VERSION ""

NS_ :

BS_:

BU_: XXX

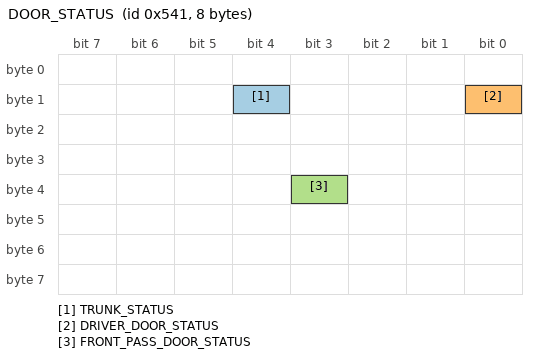
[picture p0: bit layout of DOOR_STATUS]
BO_ 1345 DOOR_STATUS: 8 XXX
 SG_ TRUNK_STATUS : 12|1@0+ (1,0) [0|1] "" XXX
 SG_ DRIVER_DOOR_STATUS : 8|1@0+ (1,0) [0|1] "" XXX
 SG_ FRONT_PASS_DOOR_STATUS : 35|1@0+ (1,0) [0|1] "" XXX

BO_ 688 Steering?: 8 XXX
 SG_ Steering position? : 7|16@0- (1,0) [0|65535] "" XXX

BO_ 339 undefined: 8 XXX

BO_ 1363 DOOR_STATUS2: 8 XXX
 SG_ REAR_PASS_DOOR_STATUS : 23|1@0+ (1,0) [0|1] "" XXX
 SG_ RREAR_DRIVER_DOOR_STATUS : 24|1@0+ (1,0) [0|1] "" XXX

BO_ 832 LKAS_HUD: 8 XXX
 SG_ LKAS_TIMEOUT : 8|1@0+ (1,0) [0|1] "" XXX
